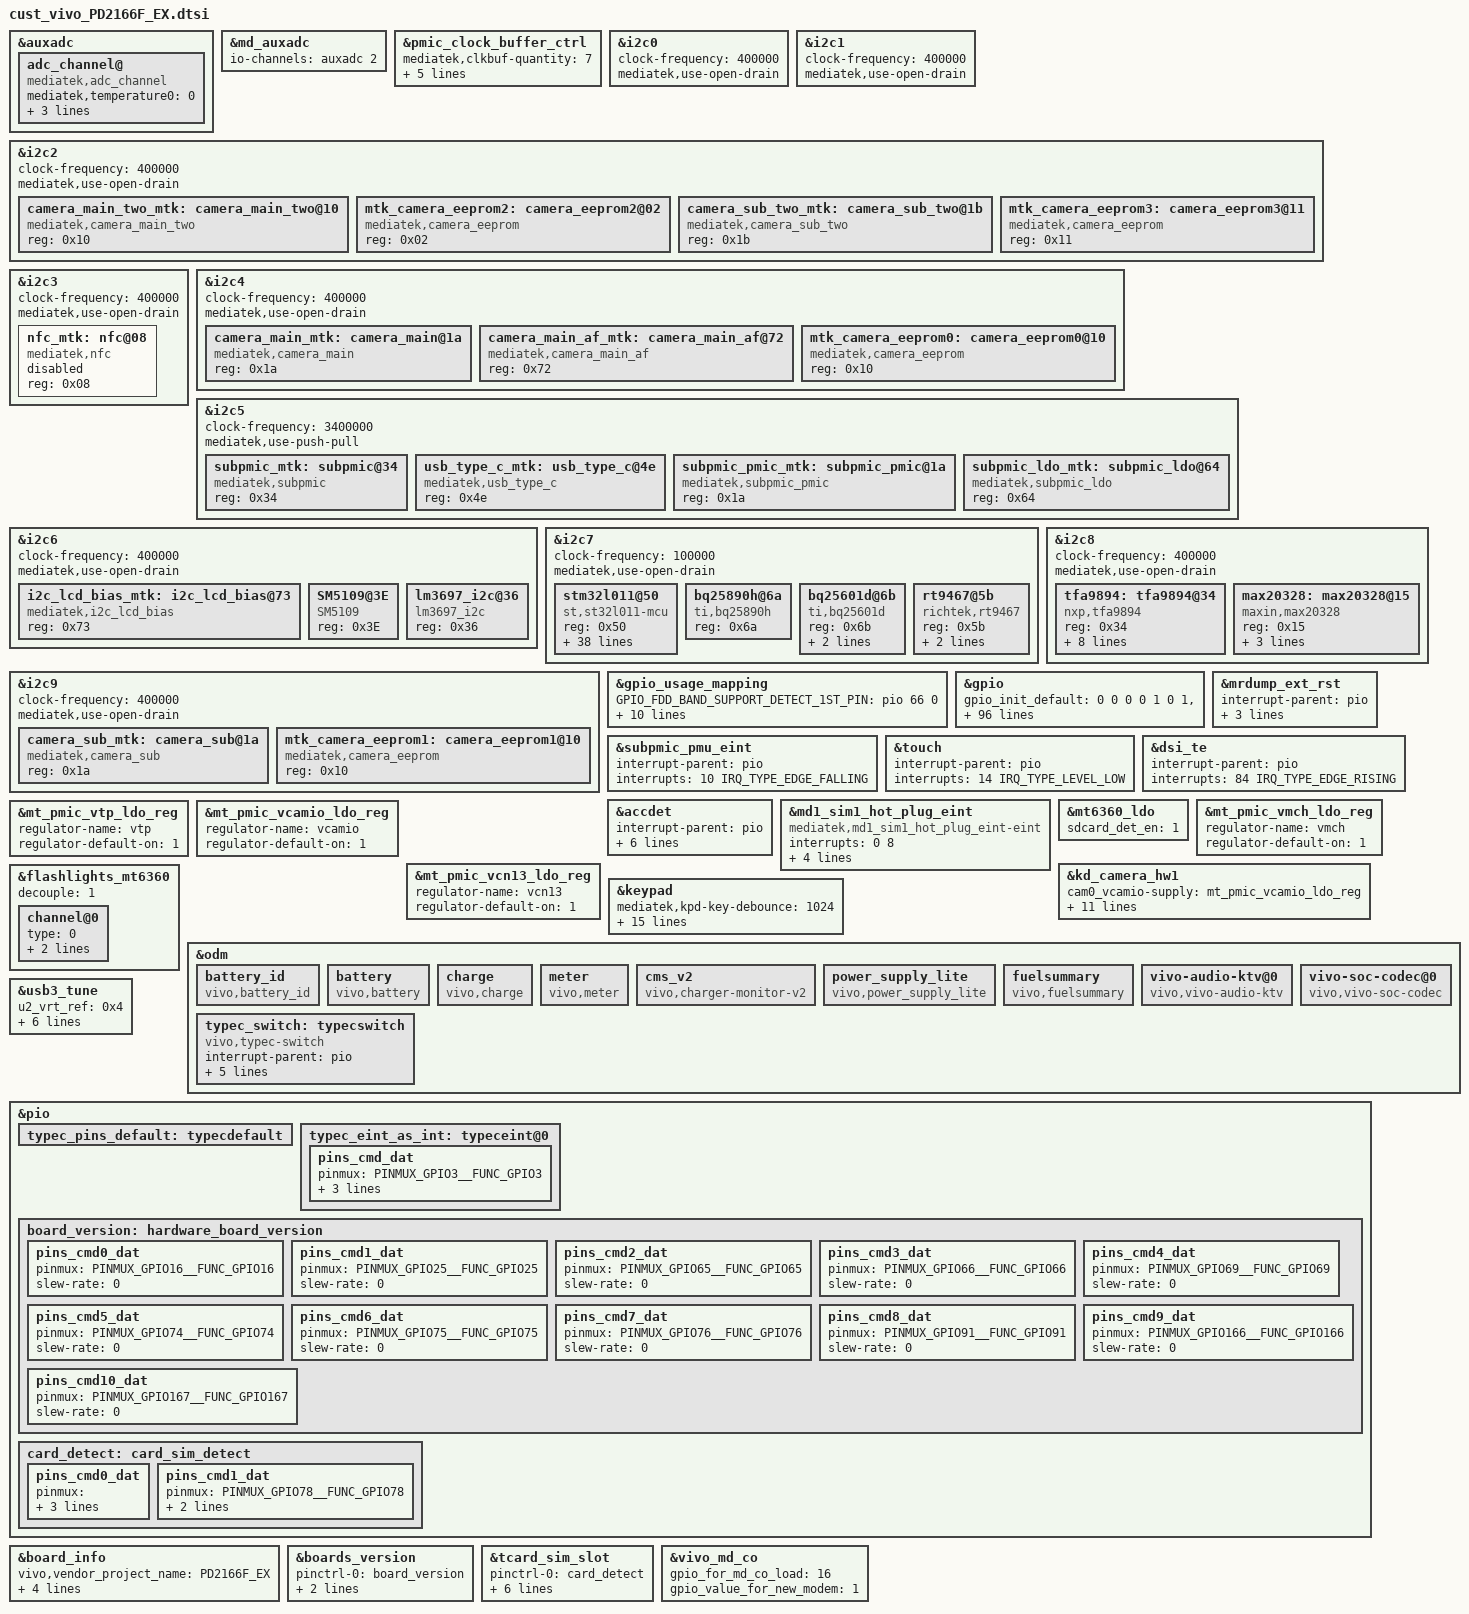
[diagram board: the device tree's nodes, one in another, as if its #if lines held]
/*
 * Generated by MTK SP DrvGen Version: 3.5.160809 for MT6833.
 * 2021-08-25 23:23:21
 * Do Not Modify The File.
 * Copyright Mediatek Inc. (c) 2016.
*/

/*************************
 * ADC DTSI File
*************************/

&auxadc {
	adc_channel@ {
		compatible = "mediatek,adc_channel";
		mediatek,temperature0 = <0>;
		mediatek,temperature1 = <1>;
		mediatek,adc_fdd_rf_params_dynamic_custom_ch = <2>;
		status = "okay";
	};
};
&md_auxadc {
	io-channels = <&auxadc 2>;
};


/*************************
 * CLK_BUF DTSI File
*************************/

&pmic_clock_buffer_ctrl {
	mediatek,clkbuf-quantity = <7>;
	mediatek,clkbuf-config = <2 1 2 2 0 0 1>;
	mediatek,clkbuf-output-impedance = <6 4 4 4 0 0 4>;
	mediatek,clkbuf-controls-for-desense = <0 4 0 4 0 0 0>;
	status = "okay";
};


/*************************
 * I2C DTSI File
*************************/

&i2c0 {
	#address-cells = <1>;
	#size-cells = <0>;
	clock-frequency = <400000>;
	mediatek,use-open-drain;
};

&i2c1 {
	#address-cells = <1>;
	#size-cells = <0>;
	clock-frequency = <400000>;
	mediatek,use-open-drain;
};

&i2c2 {
	#address-cells = <1>;
	#size-cells = <0>;
	clock-frequency = <400000>;
	mediatek,use-open-drain;

	camera_main_two_mtk:camera_main_two@10 {
		compatible = "mediatek,camera_main_two";
		reg = <0x10>;
		status = "okay";
	};
	mtk_camera_eeprom2:camera_eeprom2@02 {
		compatible = "mediatek,camera_eeprom";
		reg = <0x02>;
		status = "okay";
	};
	camera_sub_two_mtk:camera_sub_two@1b {
		compatible = "mediatek,camera_sub_two";
		reg = <0x1b>;
		status = "okay";
	};

	mtk_camera_eeprom3:camera_eeprom3@11 {
		compatible = "mediatek,camera_eeprom";
		reg = <0x11>;
		status = "okay";
	};
};

&i2c3 {
	#address-cells = <1>;
	#size-cells = <0>;
	clock-frequency = <400000>;
	mediatek,use-open-drain;
	nfc_mtk:nfc@08 {
		compatible = "mediatek,nfc";
		reg = <0x08>;
		status = "disabled";
	};

};

&i2c4 {
	#address-cells = <1>;
	#size-cells = <0>;
	clock-frequency = <400000>;
	mediatek,use-open-drain;
	camera_main_mtk:camera_main@1a {
		compatible = "mediatek,camera_main";
		reg = <0x1a>;
		status = "okay";
	};
	camera_main_af_mtk:camera_main_af@72 {
		compatible = "mediatek,camera_main_af";
		reg = <0x72>;
		status = "okay";
	};

	mtk_camera_eeprom0:camera_eeprom0@10 {
		compatible = "mediatek,camera_eeprom";
		reg = <0x10>;
		status = "okay";
	};

};

&i2c5 {
	#address-cells = <1>;
	#size-cells = <0>;
	clock-frequency = <3400000>;
	mediatek,use-push-pull;
	subpmic_mtk:subpmic@34 {
		compatible = "mediatek,subpmic";
		reg = <0x34>;
		status = "okay";
	};

	usb_type_c_mtk:usb_type_c@4e {
		compatible = "mediatek,usb_type_c";
		reg = <0x4e>;
		status = "okay";
	};

	subpmic_pmic_mtk:subpmic_pmic@1a {
		compatible = "mediatek,subpmic_pmic";
		reg = <0x1a>;
		status = "okay";
	};

	subpmic_ldo_mtk:subpmic_ldo@64 {
		compatible = "mediatek,subpmic_ldo";
		reg = <0x64>;
		status = "okay";
	};

};

&i2c6 {
	#address-cells = <1>;
	#size-cells = <0>;
	clock-frequency = <400000>;
	mediatek,use-open-drain;
	i2c_lcd_bias_mtk:i2c_lcd_bias@73 {
		compatible = "mediatek,i2c_lcd_bias";
		reg = <0x73>;
		status = "okay";
	};
	SM5109@3E {
		compatible = "SM5109";
		reg = <0x3E>;
		status = "okay";
	};
	lm3697_i2c@36 {
		compatible = "lm3697_i2c";
		reg = <0x36>;
		status = "okay";
	};
};

&i2c7 {
	#address-cells = <1>;
	#size-cells = <0>;
	clock-frequency = <400000>;
	mediatek,use-open-drain;
};

&i2c8 {
	#address-cells = <1>;
	#size-cells = <0>;
	clock-frequency = <400000>;
	mediatek,use-open-drain;
	

};

&i2c9 {
	#address-cells = <1>;
	#size-cells = <0>;
	clock-frequency = <400000>;
	mediatek,use-open-drain;
	
	camera_sub_mtk:camera_sub@1a {
		compatible = "mediatek,camera_sub";
		reg = <0x1a>;
		status = "okay";
	};

	mtk_camera_eeprom1:camera_eeprom1@10 {
		compatible = "mediatek,camera_eeprom";
		reg = <0x10>;
		status = "okay";
	};

};



/*************************
 * GPIO DTSI File
*************************/

&gpio_usage_mapping {
	GPIO_FDD_BAND_SUPPORT_DETECT_1ST_PIN = <&pio 66 0>;
	GPIO_FDD_BAND_SUPPORT_DETECT_2ND_PIN = <&pio 65 0>;
	GPIO_FDD_BAND_SUPPORT_DETECT_3RD_PIN = <&pio 25 0>;
	GPIO_SIM1_HOT_PLUG = <&pio 77 0>;
	GPIO_SIM2_SCLK = <&pio 119 0>;
	GPIO_SIM2_SRST = <&pio 120 0>;
	GPIO_SIM2_SIO = <&pio 121 0>;
	GPIO_SIM1_SIO = <&pio 122 0>;
	GPIO_SIM1_SRST = <&pio 123 0>;
	GPIO_SIM1_SCLK = <&pio 124 0>;
	GPIO_RF_PWREN_RST_PIN = <&pio 170 0>;
};

&gpio{
	gpio_init_default = <0 0 0 0 1 0 1>,
		<1 0 0 0 1 1 1>,
		<2 0 0 0 1 1 1>,
		<3 0 0 0 1 0 1>,
		<4 0 0 0 1 1 1>,
		<5 0 0 0 1 0 1>,
		<6 0 1 0 1 0 1>,
		<7 0 1 0 1 0 1>,
		<8 7 0 0 1 0 1>,
		<9 0 0 0 1 1 1>,
		<10 0 0 0 1 1 1>,
		<11 0 0 0 1 1 1>,
		<12 2 0 0 1 0 1>,
		<13 2 0 0 1 0 1>,
		<14 0 0 0 1 1 1>,
		<15 0 1 0 1 0 1>,
		<16 0 0 0 1 1 0>,
		<17 7 0 0 1 0 1>,
		<18 7 0 0 1 0 1>,
		<19 7 0 0 0 0 1>,
		<20 7 0 0 1 0 1>,
		<21 0 0 0 0 0 1>,
		<22 7 0 0 1 0 1>,
		<23 7 0 0 1 0 1>,
		<24 7 0 0 1 0 1>,
		<25 0 0 0 1 1 0>,
		<26 7 0 0 1 0 1>,
		<27 1 0 0 0 0 1>,
		<28 1 0 0 0 0 1>,
		<29 1 0 0 0 0 1>,
		<30 1 0 0 1 0 1>,
		<31 2 0 0 0 0 1>,
		<32 2 0 0 0 0 1>,
		<33 2 0 0 0 0 1>,
		<34 2 0 0 1 0 1>,
		<35 0 1 0 1 0 1>,
		<36 0 1 0 1 0 1>,
		<37 0 1 0 1 0 1>,
		<38 0 1 0 1 0 1>,
		<39 0 0 0 1 1 1>,
		<40 1 0 0 0 0 1>,
		<41 1 0 0 0 0 1>,
		<42 1 0 0 1 0 1>,
		<43 1 0 0 0 0 1>,
		<44 0 1 0 1 1 1>,
		<45 0 1 1 0 0 0>,
		<46 0 0 0 1 0 1>,
		<47 0 0 0 0 0 1>,
		<48 0 0 0 0 0 1>,
		<49 1 1 0 0 0 0>, //CAM0 clk0
		<50 1 1 0 0 0 0>, //CAM3 clk1
		<51 1 1 0 0 0 0>, //CAM2 clk2
		<52 1 1 0 0 0 0>, //CAM1 clk3
		<53 0 1 0 1 0 1>, //cam0 AVDD
		<54 0 1 0 0 0 0>, //CAM0 RST 
		<55 0 1 0 0 0 0>, //cam123 AVDD
		<56 0 1 0 0 0 0>, //CAM3 RST
		<57 0 0 0 1 0 1>,
		<58 0 1 0 0 0 0>, //CAM2 RST
		<59 0 1 0 0 0 0>, //cam0 DVDD
		<60 0 1 0 0 0 0>, //CAM1 RST
		<61 1 0 0 1 1 1>,
		<62 1 0 0 0 0 1>,
		<63 1 0 0 1 1 1>,
		<64 1 0 0 0 0 1>,
		<65 0 0 0 1 1 0>,
		<66 0 0 0 1 1 0>,
		<67 0 1 0 1 1 0>,
		<69 0 0 0 1 1 0>,
		<74 0 0 0 1 1 0>,
		<75 0 0 0 1 1 0>,
		<76 0 0 0 1 1 0>,
		<77 1 0 0 0 0 1>,
		<78 0 0 0 0 0 1>,
		<79 1 0 0 1 1 1>,
		<80 0 1 0 1 0 1>,
		<81 3 0 0 1 0 1>,
		<82 0 1 0 1 0 1>,
		<83 1 0 0 0 0 1>,
		<84 1 0 0 1 0 1>,
		<85 1 0 0 0 0 1>,
		<86 0 0 0 0 0 1>,
		<87 2 0 0 1 0 1>,
		<88 1 0 0 1 0 1>,
		<89 0 0 0 1 0 1>,
		<90 0 0 0 0 0 1>,
		<91 0 0 0 1 0 1>,
		<92 0 1 0 1 0 1>,
		<93 0 1 0 1 0 1>,
		<94 0 1 0 1 0 1>,
		<95 1 0 0 1 0 1>,
		<96 1 0 0 1 0 1>,
		<97 2 0 0 1 1 1>,
		<98 2 0 0 1 1 1>,
		<99 2 0 0 1 1 1>,
		<100 2 0 0 1 1 1>,
		<101 1 0 0 0 0 1>, //scl2 iic2
		<102 1 0 0 0 0 1>, //sda2 iic2
		<103 1 0 0 1 1 1>,
		<104 1 0 0 1 1 1>,
		<105 1 0 0 0 0 1>, //scl4 iic4
		<106 1 0 0 0 0 1>, //sda4 iic4
		<107 1 0 0 1 1 1>,
		<108 1 0 0 1 1 1>,
		<109 1 0 0 1 1 1>,
		<110 1 0 0 1 1 1>,
		<111 1 0 0 1 1 1>,
		<112 1 0 0 1 1 1>,
		<113 1 0 0 1 1 1>,
		<114 1 0 0 1 1 1>,
		<115 1 0 0 1 0 1>,
		<116 1 0 0 1 0 1>,
		<117 0 0 0 1 0 1>,
		<118 0 0 0 1 0 1>,
		<119 1 0 0 0 0 1>,
		<120 1 0 0 0 0 1>,
		<121 1 0 0 1 1 1>,
		<122 1 0 0 1 1 1>,
		<123 1 0 0 0 0 1>,
		<124 1 0 0 0 0 1>,
		<125 1 0 0 0 0 1>,
		<126 1 0 0 1 1 1>,
		<127 1 0 0 1 1 1>,
		<128 1 0 0 1 1 1>,
		<129 1 0 0 1 1 1>,
		<130 1 0 0 1 1 1>,
		<131 0 1 0 1 0 1>,
		<132 0 1 0 1 0 1>,
		<133 0 1 0 1 0 1>,
		<134 0 1 0 1 0 1>,
		<135 0 1 0 1 0 1>,
		<136 0 1 1 1 0 1>,
		<137 0 1 0 1 0 1>,
		<138 0 1 0 1 0 1>,
		<139 0 1 0 1 0 1>,
		<140 0 1 0 1 0 1>,
		<141 1 0 0 0 0 1>, //scl9 iic9
		<142 1 0 0 0 0 1>, //sda9 iic9
		<143 1 0 0 0 0 1>,
		<144 1 0 0 0 0 1>,
		<145 1 0 0 0 0 1>,
		<146 1 0 0 0 0 1>,
		<147 1 0 0 0 0 1>,
		<148 1 0 0 0 0 1>,
		<149 1 0 0 1 0 1>,
		<150 1 0 0 1 0 1>,
		<151 1 0 0 1 0 1>,
		<152 1 0 0 1 0 1>,
		<153 1 0 0 0 0 1>,
		<154 1 0 0 0 0 1>,
		<155 1 0 0 0 0 1>,
		<156 1 0 0 0 0 1>,
		<157 1 0 0 0 0 1>,
		<158 1 0 0 0 0 1>,
		<159 1 0 0 1 0 1>,
		<160 1 0 0 1 0 1>,
		<161 1 0 0 1 0 1>,
		<162 1 0 0 0 0 0>,
		<163 1 0 0 1 0 0>,
		<164 1 0 0 1 0 1>,
		<165 1 0 0 1 0 1>,
		<166 0 0 0 1 1 0>,
		<167 0 0 0 1 1 0>,
		<168 1 0 0 0 0 1>,
		<169 1 0 0 0 0 1>,
		<170 0 1 1 1 0 1>,
		<171 1 0 0 0 0 1>,
		<172 1 0 0 0 0 1>,
		<173 1 0 0 0 0 1>,
		<174 1 0 0 0 0 1>,
		<175 1 0 0 0 0 1>,
		<176 1 0 0 0 0 1>,
		<177 1 0 0 0 0 1>,
		<178 1 0 0 0 0 1>,
		<179 1 0 0 0 0 1>,
		<180 1 0 0 0 0 1>,
		<181 1 0 0 0 0 1>,
		<182 1 0 0 0 0 1>,
		<183 1 0 0 0 0 1>,
		<184 1 0 0 0 0 1>,
		<185 1 0 0 0 0 1>,
		<186 1 0 0 0 0 1>,
		<187 0 1 0 1 0 1>,
		<188 1 0 0 0 0 0>,
		<189 1 0 0 1 0 0>,
		<190 1 0 0 0 0 0>,
		<191 1 0 0 1 0 0>,
		<192 0 0 0 1 0 1>,
		<193 0 0 0 1 0 1>,
		<194 0 0 0 1 0 1>,
		<195 0 0 0 1 0 1>,
		<196 0 0 0 1 0 1>,
		<197 0 0 0 1 0 1>,
		<198 0 0 0 1 0 1>,
		<199 0 0 0 1 0 1>,
		<200 0 0 0 1 0 1>;
};


/*************************
 * EINT DTSI File
*************************/

#include <dt-bindings/interrupt-controller/irq.h>
#include <dt-bindings/interrupt-controller/arm-gic.h>

&mrdump_ext_rst {
	interrupt-parent = <&pio>;
	interrupts = <1 IRQ_TYPE_LEVEL_LOW>;
	deb-gpios = <&pio 1 0>;
	debounce = <512000>;
	status = "okay";
};

&subpmic_pmu_eint {
	interrupt-parent = <&pio>;
	interrupts = <10 IRQ_TYPE_EDGE_FALLING>;
	status = "okay";
};

&touch {
	interrupt-parent = <&pio>;
	interrupts = <14 IRQ_TYPE_LEVEL_LOW>;
	status = "okay";
};

&dsi_te {
	interrupt-parent = <&pio>;
	interrupts = <84 IRQ_TYPE_EDGE_RISING>;
	status = "okay";
};

&accdet {
	interrupt-parent = <&pio>;
	interrupts = <2 IRQ_TYPE_LEVEL_LOW>,
			<3 IRQ_TYPE_LEVEL_LOW>;
	deb-gpios = <&pio 2 0>;
	deb-rgpios = <&pio 3 0>;
	debounce = <256000>;
	debounce1 = <256000>;
	status = "okay";
};


/*************************
 * MD1_EINT DTSI File
*************************/

&md1_sim1_hot_plug_eint {
	compatible = "mediatek,md1_sim1_hot_plug_eint-eint";
	interrupts = <0 8>;
	debounce = <0 100000>;
	dedicated = <0 0>;
	src_pin = <0 1>;
	sockettype = <0 0>;
	status = "okay";
};


/*************************
 * PMIC DTSI File
*************************/
&mt6360_ldo {
	sdcard_det_en = <1>;
};

&mt_pmic_vmch_ldo_reg {
	regulator-name = "vmch";
	regulator-default-on = <1>; /* 0:skip, 1: off, 2:on */
	status = "okay";
};

&mt_pmic_vtp_ldo_reg {
	regulator-name = "vmch";
	regulator-default-on = <1>; /* 0:skip, 1: off, 2:on */
	status = "okay";
};
&mt_pmic_vcamio_ldo_reg {
	regulator-name = "vcamio";
	regulator-default-on = <1>; /* 0:skip, 1: off, 2:on */
	status = "okay";
};
&mt_pmic_vtp_ldo_reg {
	regulator-name = "vtp";
	regulator-default-on = <1>; /* 0:skip, 1: off, 2:on */
	status = "okay";
};

&mt_pmic_vcn13_ldo_reg{
	regulator-name = "vcn13";
	regulator-default-on = <1>; /* 0:skip, 1: off, 2:on */
	status = "okay";
};
&kd_camera_hw1 {
	cam0_vcamio-supply = <&mt_pmic_vcamio_ldo_reg>;/*6365 vcamio*/
	cam1_vcamio-supply = <&mt_pmic_vcamio_ldo_reg>;
	cam2_vcamio-supply = <&mt_pmic_vcamio_ldo_reg>;
	cam3_vcamio-supply = <&mt_pmic_vcamio_ldo_reg>;
	cam1_vcamd-supply = <&mt_pmic_vcn13_ldo_reg>;/*6365 DVDD*/
	cam0_vcamaf_def-supply = <&mt_pmic_vtp_ldo_reg>;/*6360 AF*/
	cam0_enable_sensor = "s5kjn1sq03pd2166_mipi_raw ov13b10pd2166_mipi_raw";
	cam1_enable_sensor = "s5k4h7pd2166_mipi_raw hi1634qpd2166_mipi_raw";
	cam2_enable_sensor = "gc02m1pd2166_mipi_raw";
	cam3_enable_sensor = "gc02m1bpd2166_mipi_mono";
	status = "okay";
};

&camera_main_af_mtk{
         //vcamaf-supply = <&mt_pmic_vtp_ldo_reg>;
         status = "okay";
};

&flashlights_mt6360 {
	decouple = <1>;
	channel@0 {
			type = <0>;
			ct = <0>;
			part = <0>;
	};
};

/*************************
 * POWER DTSI File
*************************/



/*************************
 * KPD DTSI File
*************************/

&keypad {
	mediatek,kpd-key-debounce = <1024>;
	mediatek,kpd-sw-pwrkey = <116>;
	mediatek,kpd-hw-pwrkey = <8>;
	mediatek,kpd-sw-rstkey  = <114>;
	mediatek,kpd-hw-rstkey = <17>;
	mediatek,kpd-use-extend-type = <0>;
	/*HW Keycode [0~71] -> Linux Keycode*/
	mediatek,kpd-hw-map-num = <72>;
	mediatek,kpd-hw-init-map = <115 0 0 0 0 0 0 0 0 0 0 0 0 0 0 0 0 0 0 0 0 0 0 0 0 0 0 0 0 0 0 0 0 0 0 0 0 0 0 0 0 0 0 0 0 0 0 0 0 0 0 0 0 0 0 0 0 0 0 0 0 0 0 0 0 0 0 0 0 0 0 0 >;
	mediatek,kpd-pwrkey-eint-gpio = <0>;
	mediatek,kpd-pwkey-gpio-din  = <0>;
	mediatek,kpd-hw-dl-key0 = <17>;
	mediatek,kpd-hw-dl-key1 = <0>;
	mediatek,kpd-hw-dl-key2 = <8>;
	mediatek,kpd-hw-recovery-key = <17>;
	mediatek,kpd-hw-factory-key = <0>;
	status = "okay";
};

/* Chris Lee add for battery&charge start */
#ifdef CONFIG_VIVO_CHARGING_NEW_ARCH
#ifdef CONFIG_VIVO_CHARGING_DTS_MOVE_HEAD_FILE
&odm {
	battery_id {
		compatible = "vivo,battery_id";
		status = "okay";
	};

	battery: battery {
		compatible = "vivo,battery";
		status = "okay";
	};

	charge: charge {
		compatible = "vivo,charge";
		status = "okay";
	};

	meter: meter {
		compatible = "vivo,meter";
		status = "okay";
	};

	cms_v2: cms_v2 {
		compatible = "vivo,charger-monitor-v2";
		status = "okay";
	};

	power_supply_lite: power_supply_lite {
		compatible = "vivo,power_supply_lite";
		status = "okay";
	};

	fuelsummary: fuelsummary {
		compatible = "vivo,fuelsummary";
		status = "okay";
	};
};

#else

&battery_id {
	status = "okay";
	compatible = "vivo,battery_id";

	vivo,bat-adc-ctrl-gpio = <&pio 131 0>;

	io-channels = <&auxadc 3>;
	io-channel-names = "battery_id_adc";

	vivo,bat-name = "UNKNOWN","B-O8 ATL-FMT 4910","B-O8 LW-XWD 4910", "B-O8 ATL-XDN 4910";
};

&battery {
	status = "okay";
	compatible = "vivo,battery";

	io-channels = <&auxadc 0>,
		<&auxadc 4>;
	io-channel-names = "primary_board_therm",
		"parallel_board_therm";

	vivo,low-volt-threshold = <3400>;
	vivo,soft-rise-percent = <90>;
	vivo,soft-rise-cumulative = <10>;
	vivo,soft-rise-keep-cumulative = <14>;
	vivo,percnet-sync-delta = <4>;
	vivo,percnet-sync-cumulative = <9>;
	vivo,full-sync-cumulative = <3>;
	vivo,soft-term-percent = <99>;
	vivo,soft-term-cumulative = <48>;
};

&charge {
	status = "okay";
	compatible = "vivo,charge";

	vivo,chg-wdt-s = <40>;
	vivo,re-chg-voltage-mv = <100>;
	vivo,prechg-voltage-mv = <3000>;
	vivo,iprechg-current-ma = <300>;
	vivo,iterm-current-ma = <256>;
	vivo,vreg-voltage-mv = <4430>;
	vivo,vindpm-voltage-mv = <4600>;
	vivo,sys-voltage-min-mv= <3300>;
	vivo,boostv-voltage-mv = <5150>;
	vivo,boostv-ilimit-ma = <1800>;
	vivo,ovp-voltage-mv = <15000>;

	vivo,battery-id-vreg-mv = <4430 4430 4430 4430 4430 4430>;
	/*
	 * 0  auto detect charging
	 * 1  vivo-normal chargine
	 * 2  vivo-single engine charging
	 * 3  vivo-dual engine charging
	 * 4  vivo-flash charging
	 */
	vivo,charge-scheme = <0>;
	vivo,direct-charger-enable;

	/*
	 * SUPPORTED_ADAPTER_DEFAULT = 0,
	 * SUPPORTED_ADAPTER_VIVO_LV_DCHG_5V_4500MA = 1,
	 * SUPPORTED_ADAPTER_VIVO_HV_DCHG_10V_2250MA = 2,
	 * SUPPORTED_ADAPTER_QC20__9V_2000MA = 3,
	 * SUPPORTED_ADAPTER_VIVO_HV_DCHG_10V_4000MA = 4,
	 * SUPPORTED_ADAPTER_MAX,
	 */
	vivo,supported-adapter = <3>;

	//parameter for 9V2A
	vivo,primary-ichg-max-ma = <2048>;
	vivo,parallel-ichg-max-ma = <1720>;

	vivo,flashchg-spec-ma = <2000 3300 8000>;
	vivo,fastchg-spec-ma = <2000 2100 3800>;
	vivo,normalchg-spec-ma = <2000 1500 2300>;

	/* 0---PMIC; 1---CHGIC */
	vivo,vbus-detect-source = <1>;

	//vivo,usboe-gpio = <&pio 184 0>;

	/*ffc*/
	//vivo,ffc-enable;
	vivo,ffc-iterm-ma = <(-750)>;
	vivo,ffc-vreg-mv = <4520>;
	vivo,ffc-temperature-range = <150 450>;
	vivo,ffc-full-vbat-table-size = <3>;
	vivo,ffc-full-vbat-table = <4534 4520 4520>;
	vivo,ffc-full-ibat-table-size = <3>;
	vivo,ffc-full-ibat-table = <150 199 (-699)>,
		<200 349 (-958)>,
		<350 449 (-1137)>;
};

&meter {
	status = "okay";
	compatible = "vivo,meter";

	vivo,load-capacity-delta-max = <60>;
	vivo,poweron-delta-capacity = <20>;
	vivo,poweron-low-capacity = <3>;
	vivo,volt-car-delta = <8>;
	vivo,car-volt-delta = <6>;
	vivo,meter-res-compesate = <10>;
	vivo,ocv-board-compesate = <0>;

	/* 0---AGING_UNSUPPORTED; 1---DRIVER_SUPPORTED; 2---USPACE_SUPPORTED */
	vivo,battery-aging-support = <2>;

	vivo,capacity-mAh = <4910>;
	/*COLD_CHG COLD_DISCHG NORMAL_CHG NORMAL_DISCHG*/
	vivo,car-tune-value = <1000 1000 1000 1000>,
		<1000 1000 1000 1000>,
		<1000 1000 1000 1000>,
		<1030 1010 1050 1010>,
		<1000 1000 1000 1000>,
		<1000 1000 1000 1000>;

	vivo,bats-qmax = <3270 3460 3440 3790 3870>,
		<4250 4380 4741 4970 4950>,
		<3450 4150 4660 4780 4799>,
		<4300 4450 4700 4970 4975>,
		<3276 3346 3458 3524 3514>,
		<3600 3677 3800 3873 3862>;

	/* car-tune adjust remap */
	vivo,car-tune-adjust-enable;
	vivo,car-tune-adjust-size = <3>;
	vivo,car-tune-adjust-table = <0 10 (340) 7>,
		<11 20 (-30) 10>,
		<21 100 (-30) 11>;

	#include "bat_setting/PD2166_battery_table.dtsi"
};

&cms_v2 {
	compatible = "vivo,charger-monitor-v2";
	status = "okay";

	default_board: single_charger_board {
		       /*default board: keep in xxxxxx*/
		       support-board-version = "xxxxxx";

		       vivo,bat-det-method = <0>;//r:0, rc:1, eprom:2, ex-fg:3
		       vivo,bat-id-gpio = <&pio 131 0>;
				#include "bat_setting/PD2166_battery_chg_params.dtsi"

		       /*
			  CHG0__CHARGING_TECHNOLOGY_NONE = 0,
			  CHG1__NORMAL_CHARGING,			//5V/2A normal charging
			  CHG2__QC2_CHARGING,				//9V/2A	QC2.0 charging
			  CHG3__LOW_VOLTAGE_DIRECT_CHARGING,		//5V/4.5A direct charging
			  CHG4__SINGLE_IC_DIV2_CHARGING,		//single IC Div/2 charging
			  CHG5__DUAL_IC_DIV2_CHARGING,			//Dual IC Div/2 charging
			  CHG6__DUAL_IC_DUAL_BATTERY_DIV2_CHARGING,	//Dual IC Div/2 charging
			  CHGX__CHARGING_TECHNOLOGY_MAX,
			*/
		       vivo,charging-technology = <2>;

		       //vivo,no-bat-warning;
		       //vivo,no-chg-timeout;
		       vivo,chg-timeout-mins = <900>;

		       //high temperature charger current control enable
		       vivo,htccc-enable;
		       vivo,htccc-data = <46 53 4100000 100000>;

		       //vivo,fbon-scale-enable;/*disable default*/
		       vivo,fbon-scale-data = <2 100 100>;

		       //vivo,switch-scale-enable;/*disable from rom4.0*/
		       vivo,switch-scale-data = <75 53>;

		       vivo,calling-scale-enable;
		       vivo,calling-scale-data = <100 21>;/*ibat:3900 * 0.54 = 2106,more than 1500,not exit dchg*/
		       vivo,calling-dchg-disable;

		       vivo,weixin-calling-scale-enable;
		       vivo,weixin-calling-scale-data = <100 112>;/*5000mA*/

		       //vivo,fixed-scale-enable;
		       vivo,fixed-scale-data = <120 3800 0>;/*dchg fixed time adjust the max ibat,disable default*/

		       /*data processing : batt-temp*/
		       vivo,dp-batt-temp-enable;
		       vivo,dp-batt-temp-data = <100>;

		       /* charging current for devices in exhibition mode */
		       vivo,exhibition-mode-current-primary = <2048>;
		       vivo,exhibition-mode-current-parallel = <0>;

		       /*default tc parameter*/
		       //single charger ibat scale base on temperature battery cell info:1C/1.2C 3960mah
		       /* tmin, tmax, data, volt1, data_ex1, volt2, data_ex2. */
		        vivo,normal-tc-row-col = <6 9>;
		       vivo,normal-tc-data = <530 8888 0 0 0 0 0 0 0>,
			       <450 529 65 0 0 0 0 0 0>,
			       <150 449 78 0 0 0 0 0 0>,
			       <100 149 78 4200000 54 0 0 0 0>,
			       <20 99 54 0 0 0 0 0 0>,
			       <(-8888) 19 0 0 0 0 0 0 0>;

		       /*flash tc parameter*/
		       vivo,flash-normal-tc-row-col = <9 9>;
		       vivo,flash-normal-tc-data = <550 8888 0 0 0 0 0 0 0>,
			       <450 549 50 0 0 0 0 0 0>,
			       <350 449 202 4200000 152 4300000 120 4460000 90>,
			       <200 349 202 4200000 152 4300000 120 4460000 90>,
			       <150 199 152 4200000 121 4460000 80 0 0>,
			       <100 149 100 0 0 0 0 0 0>,
			       <50 99 70 4200000 50 0 0 0 0>,
			       <0 49 50 0 0 0 0 0 0>,
			       <(-8888) (-1) 0 0 0 0 0 0 0>;

		       /*adjust fastchg base on board temperature and fb off*/
		       vivo,intell-charge-enable;
		       vivo,parallel-temp-enable = <1 1>;//<x y> x:fb-on y:fb-off

		       /* Flash charge fb-on intell param */
		       vivo,primary-fbon-tc-row-col = <7 3>;
		       vivo,primary-fbon-tc-data = <421 8888 1600>,
			       <411 420 2300>,
			       <401 410 3300>,
			       <391 400 3800>,
			       <381 390 4300>,
			       <361 380 6000>,
			       <(-8888) 360 8000>;

		       vivo,parallel-fbon-tc-row-col = <1 3>;
		       vivo,parallel-fbon-tc-data = <(-8888) 8888 0>;

		       /* Flash charge fb-off intell param */
		       vivo,primary-fboff-tc-row-col = <6 3>;
		       vivo,primary-fboff-tc-data = <421 8888 1600>,
			       <409 420 3100>,
			       <390 408 4000>,
			       <371 389 4300>,
			       <351 370 5200>,
			       <(-8888) 350 8000>;
		       vivo,parallel-fboff-tc-row-col = <1 3>;
		       vivo,parallel-fboff-tc-data = <(-8888) 8888 0>;

		       /* 9v Fast charge fb-on intell param */
		       vivo,9v-primary-fbon-tc-row-col = <7 3>;
		       vivo,9v-primary-fbon-tc-data = <481 8888 500>,
			       <471 480 700>,
			       <451 470 1000>,
			       <421 450 1500>,
			       <391 420 1600>,
			       <371 390 1800>,
			       <(-8888) 370 2000>;
		       vivo,9v-parallel-fbon-tc-row-col = <8 3>;
		       vivo,9v-parallel-fbon-tc-data = <461 8888 0>,
					<451 460 300>,
					<431 450 500>,
			       <411 430 600>,
			       <401 410 800>,
			       <381 400 1100>,
			       <361 380 1300>,
			       <(-8888) 360 1500>;
		       // second parallel parameter, for rt9467
		       vivo,9v-2nd-parallel-fbon-tc-row-col = <6 3>;
		       vivo,9v-2nd-parallel-fbon-tc-data = <431 8888 300>,
			       <411 430 500>,
			       <391 410 800>,
			       <371 390 1000>,
			       <351 370 1300>,
			       <(-8888) 350 1500>;


		       /* 9v Fast charge fb-off intell param */
		       vivo,9v-primary-fboff-tc-row-col = <6 3>;
		       vivo,9v-primary-fboff-tc-data = <431 8888 500>,
			       <416 430 1100>,
			       <406 415 1300>,
			       <386 405 1600>,
			       <371 385 1900>,
			       <(-8888) 370 2000>;
		       vivo,9v-parallel-fboff-tc-row-col = <6 3>;
		       vivo,9v-parallel-fboff-tc-data = <431 8888 500>,
			       <411 430 800>,
			       <396 410 1100>,
			       <386 395 1300>,
			       <371 385 1600>,
			       <(-8888) 370 1700>;
		       // second parallel parameter, for rt9467
		       vivo,9v-2nd-parallel-fboff-tc-row-col = <6 3>;
		       vivo,9v-2nd-parallel-fboff-tc-data = <431 8888 500>,
			       <411 430 700>,
			       <386 410 1150>,
			       <376 385 1300>,
			       <371 375 1600>,
			       <(-8888) 370 1700>;


		       /* 5v Normal charge fb-on intell param */
		       vivo,5v-primary-fbon-tc-row-col = <5 3>;
		       vivo,5v-primary-fbon-tc-data = <441 8888 500>,
					<431 440 800>,
			       <421 430 1000>,
			       <411 420 1500>,
			       <(-8888) 410 2000>;
		       vivo,5v-parallel-fbon-tc-row-col = <1 3>;
		       vivo,5v-parallel-fbon-tc-data = <(-8888) 8888 0>;

		       /* 5v Normal charge fb-off intell param */
		       vivo,5v-primary-fboff-tc-row-col = <5 3>;
		       vivo,5v-primary-fboff-tc-data = <441 8888 500>,
					<431 440 800>,
			       <421 430 1000>,
			       <411 420 1500>,
			       <(-8888) 410 2000>;
		       vivo,5v-parallel-fboff-tc-row-col = <1 3>;
		       vivo,5v-parallel-fboff-tc-data = <(-8888) 8888 0>;

		       // Direct charging param
		       vivo,direct-charger-enable;//porting_check
		       vivo,ex-bms-psy-name = "bq_bms";

		       // bat_baord, usb_conn, pcb_conn(master_bat_conn), bat_conn
		       vivo,dchg-ntc-protect-enable;
		       vivo,dchg-ntc-protect-data = <750 800 850 850>;

		       vivo,adapter-cooldown-data = <900 850 3400>;
		       /*adapter power derate*/
		       vivo,adapter-power-derate-enable;

		       /* usb connecter protect param
			* USB_PROTECT_NONE = 0,
			* USB_CONN_TEMP_HEAT_PROTECT = BIT(0),
			* USB_ID_PROTECT = BIT(1),
			*/
		       vivo,usb-connecter-protect-enable = <1>;
		       vivo,usb-id-protect-data= <1100 1547 500>;/* 500K, 2M, fcc */
		       vivo,usb-conn-heat-protect-data-row-col = <2 4>;
		       vivo,usb-conn-heat-protect-data= <260 8888 670 620>,
			       <(-8888) 259 570 520>;

		       /*
			* max vbus of adapter:11v, max ibus of adapter:5A
			* min voltage of battery for half chg:3500mV,max voltage of battery for half charge:4100mV,
			* 5V2A charge min current threshold: 1000mA,5V2A charge max current threshold:2100mA,
			* flash charge min current threshold:5000mA,flash charge max current threshold:11000mA
			*/

		       /*default parameter*/
		       vivo,charge-param-judge-threshold = <9 2 3500 4300 1000 2100 2100 4600>;
		       /* factory mode charging test param */
		       vivo,charge-test-param-row-col = <12 3>;
		       vivo,charge-test-param-data = <0 0 5500>, /* cable resistance, min value, max value */
			       <0 0 5500>, /* master ibus, min ibus, max ibus */
			       <0 0 5500>, /* slave ibus, min ibus, max ibus */
			       <1 20 40>, /* batt therm ntc, min value, max value */
			       <1 20 45>, /* board therm ntc, min value, max value */
			       <0 20 50>, /* sub charger ntc, min value, max value */
			       <0 20 45>, /* usb con ntc, min value, max value */
			       <0 20 45>, /* usb con 1 ntc, double usb NTC, min value, max value */
			       <0 20 45>, /* bat btb master ntc, min value, max value */
			       <0 20 50>, /* bat btb sub ntc, min value, max value */
			       <0 20 50>, /* bat board ntc, min value, max value */
			       <0 20 50>; /* wireless charge coil ntc, min value, max value */

		       /*flash parameter*/
		       vivo,flash-charge-param-judge-threshold = <11 3 3500 4100 1000 2200 4000 8200>;
		       /* factory mode charging test param */
		       vivo,flash-charge-test-param-row-col = <12 3>;
		       vivo,flash-charge-test-param-data = <1 0 5500>, /* cable resistance, min value, max value */
			       <1 0 5500>, /* master ibus, min ibus, max ibus */
			       <0 0 5500>, /* slave ibus, min ibus, max ibus */
			       <1 20 40>, /* batt therm ntc, min value, max value */
			       <1 20 45>, /* board therm ntc, min value, max value */
			       <0 20 50>, /* sub charger ntc, min value, max value */
			       <1 20 45>, /* usb con ntc, min value, max value */
			       <0 20 45>, /* usb con 1 ntc, double usb NTC, min value, max value */
			       <1 20 45>, /* bat btb master ntc, min value, max value */
			       <0 20 50>, /* bat btb sub ntc, min value, max value */
			       <0 20 50>, /* bat board ntc, min value, max value */
			       <0 20 50>; /* wireless charge coil ntc, min value, max value */
	       };
};

&power_supply_lite {
	status = "okay";
	compatible = "vivo,power_supply_lite";
};

&fuelsummary {
	status = "okay";
	compatible = "vivo,fuelsummary";

	/************************************************************
	 *
	 *  0   vivo-fastchg
	 *  1   qcom-dualchg
	 *  2   mtk-dualchg
	 *  3   qcom-normchg
	 *  4   mtk-normchg
	 *
	 ***********************************************************/
	chg-scheme = <2>;
	fex-version = <3>;
	fbon-ibat = <(-900)>;
	fboff-ibat = <(-1000)>;

	/* 0---AGING_UNSUPPORTED; 1---DRIVER_SUPPORTED; 2---USPACE_SUPPORTED */
	vivo,battery-aging-support = <2>;
};

#endif

&i2c7 {
	#address-cells = <1>;
	#size-cells = <0>;
	status = "okay";
	clock-frequency = <100000>;

	stm32l011@50 {
		compatible = "st,st32l011-mcu";
		reg = <0x50>;

		//vpower-ldo-supply = <&mt_pmic_vcn33_2_wifi_ldo_reg>;
		vivo,power-gpio = <&pio 74 0>;//ZC_LDO_EN
		vivo,int-gpio = <&pio 8 0>;//MCU_INT_AP
		//vivo,usbsel-gpio = <&pio 8 0>;//USB_SW_EN
		vivo,shift-en-gpio = <&pio 72 0>;//SHIFT_EN
		vivo,chgic-version-gpio = <&pio 16 0>;//°æ±¾Ê¶±ð
		vivo,sbu-pwr-gpio = <&pio 17 0>;
		ti,temp-cold-degc = <2>;
		ti,temp-hot-degc = <43>;
		vivo,total-limit-max-ma = <8000>;
		vivo,bigdata-collect-time-limit = <95>;//seconds
		vivo,direct-charger-enable;//porting_check

		/*FFC charge: */
		vivo,ffc-support;
		vivo,ffc-temperature-range = <150 450>;
		//vivo,ffc-param-tuning-enable = <1963>;
		vivo,ffc-cc-to-cv-ibat-thr-rc = <1 3>;
		/*<Tmin Tmax current>*/
		vivo,ffc-cc-to-cv-ibat-thr-table = <150 450 4900>;
		vivo,ffc-dchg-cv-mv-rc = <3 2>;
		/*btb_cv,fg_cv*/
		vivo,ffc-dchg-cv-mv-table = <4460 4460>,/*default*/
			<4534 4534>,/*single_charging*/
			<4534 4534>;/*dual_charging*/

		vivo,cout-int-gpio = <&pio 15 0>;

		vivo,sbu-cable-id-detect-enable;
		vivo,sbu-detect-rely-usb-switch;

		vivo,bat-board-temp-enable = <1>;
		vivo,usb-conn-temp-enable = <3>;
		vivo,bat-conn-temp-enable = <1>;

		vivo,master-bat-conn-temp-enable = <2>;
		vivo,dchg-exit-ntc-threshold = <700 650 700 700 1200>;

		/* BQ25970_SINGLE_DCHG:
		 * DCHG_SINGLE_TYPE_22P5W = 0,
		 * DCHG_SINGLE_TYPE_33W = 1,
		 * DCHG_SINGLE_TYPE_44W = 2,
		 * BQ25970_DUAL_DCHG:DCHG_DUAL_TYPE_44W = 3,
		 */
		vivo,dchg-supported-type = <2>;
		/*adapter power derate*/
		vivo,adapter-power-derate-enable;

		//vivo,single-charger-enable;
		vivo,adapter-sha-encryption;

		io-channels = <&auxadc 5>,
			<&auxadc 6>;

		io-channel-names = "sbu2_cable_id_adc",
			"sbu1_cable_id_adc";

		/*cable r limit table :
		  <rmin,rmax, dchg_ibus_max, cable_id_type, limit_count>
		  cable_id_type: 0:effective cable id, 1:other(default) cable id
		 */
		vivo,cable-r-limit-table-rc = <9 5>;
		vivo,cable-r-limit-table = <(-8888) 271 4000 0 0>,
			<272 329 3000 0 0>,
			<330 394 2250 0 0>,
			<395 505 1800 0 0>,
			<506 8888 0 0 0>,
			<(-8888) 329 3000 1 0>,
			<330 394 2250 1 0>,
			<395 505 1800 1 0>,
			<506 8888 0 1 0>;

		/*load firmware profile*/
		vivo,fw-id-range-pct = <100>;
		#include "bat_setting/mcu-firmware-data-44w-notbat_notbus.dtsi"
		#include "bat_setting/mcu-firmware-data-44w-ln8000-notbat-notbus.dtsi"
	};

	bq25890h@6a {
		compatible = "ti,bq25890h";
		reg = <0x6a>;

		//vivo,int-gpio = <&pio 44 0>;
	};

	bq25601d@6b {
		compatible = "ti,bq25601d";
		reg = <0x6b>;

		vivo,int-gpio = <&pio 44 0>;
		vivo,enable-gpio = <&pio 187 0>;
	};

	rt9467@5b {
		compatible = "richtek,rt9467";
		reg = <0x5b>;

		vivo,int-gpio = <&pio 44 0>;
		vivo,enable-gpio = <&pio 187 0>;
	};
};
#endif
/* Chris Lee add for battery&charge end */

/*************************
 * usb DTSI File
*************************/
&usb3_tune {
	u2_vrt_ref = <0x4>;
	u2_term_ref = <0x4>;
	u2_enhance = <0x3>;
	u2_discth = <0xa>;
	u2_vrt_ref_host = <0x6>;
	u2_term_ref_host = <0x5>;
	u2_enhance_host = <0x2>;
};
/* xudong add for audio config start */
&odm {
	vivo-audio-ktv@0 {
		compatible = "vivo,vivo-audio-ktv";
		status = "okay";
	};

	vivo-soc-codec@0 {
		compatible = "vivo,vivo-soc-codec";
		status = "okay";
	};

	typec_switch:typecswitch {
		compatible = "vivo,typec-switch";
		interrupt-parent = <&pio>;
		interrupts = <3 IRQ_TYPE_LEVEL_LOW 3 0>; /* usb plug in is low level */
		deb-gpios = <&pio 3 0>;
		debounce = <256000>;
		pinctrl-names = "default", "typec_eint_as_int";
		pinctrl-0 = <&typec_pins_default>;
		pinctrl-1 = <&typec_eint_as_int>;
		status = "okay";
	};
};

&pio {
	typec_pins_default: typecdefault {
	};
	typec_eint_as_int: typeceint@0 {
		pins_cmd_dat {
			pinmux = <PINMUX_GPIO3__FUNC_GPIO3>;
			slew-rate = <0>;
			bias-pull-up; /* prevent from leaking power */
			input-enable; /* not using default config */
		};
	};
};
&i2c8{
	tfa9894: tfa9894@34 {
		status = "okay";
		compatible = "nxp,tfa9894";
		#sound-dai-cells = <1>;
		reg = <0x34>;
		vivo,tfa98xx-version = "tfa9894";
		vivo,tfa98xx-config = "tfa98xx_PD2166F_EX.cnt";
		vivo,tfa98xx-impedance-min = <6000>;
		vivo,tfa98xx-impedance-max = <10000>;
		vivo,tfa98xx-frequency-min = <600>;
		vivo,tfa98xx-frequency-max = <900>;
		vivo,tfa98xx-Qt-min = <110>;
		reset-gpio = <&pio 139 0>;
	};
	max20328:max20328@15 {
		status = "okay";
		#sound-dai-cells = <0>;
		compatible = "maxin,max20328";
		reg = <0x15>;
		max,usbc-ic-mode = <0>; /* max20328: 0; fsa4480: 1 */
		jack-type = <1>;   /*0:3.5mm, 1:Type-c*/
		switch-type = <0>; /*0:max20328, 1:FS4480*/
	};
};
/* xudong add for audio config end */


/* add board info fdt node by corebsp begin */
&board_info {
	vivo,vendor_project_name = "PD2166F_EX";
	vivo,vendor_project_cpu = "MT6833";
	vivo,vendor_project_freq = "2.2";
	vivo,vendor_project_cpunum = <8>;
	vivo,vendor_cpu_set = "Dimensity_700";
};

&boards_version {
	pinctrl-names = "default";
	pinctrl-0 = <&board_version>;
	gpio_nums = <11>;
	gpios = <16 25 65 66 69 74 75 76 91 166 167>;
	/* if use pcb version,need to define:pcb_gpio_nums pcb_gpios pcb_maps_nums pcb_gpios_maps */
	/*pcb_gpio_nums = <2>;*/
	/*pcb_gpios = <107 108>;*/
	/* 00:MP_0.1, 01:MP_0.2, 10:MP_0.3, 11:MP_0.4 */
	/*pcb_maps_nums = <8>;*/
	/*pcb_gpios_maps = <0x0 0x1 0x1 0x2 0x2 0x3 0x3 0x4>;*/
};

&tcard_sim_slot {
	pinctrl-names = "default";
	pinctrl-0 = <&card_detect>;
	vivo,sim1-need-detect;
	vivo,sim2-need-detect;
	vivo,sim1-detect-high;
	vivo,sim2-detect-high;

        card-detect-sim1,gpios = <&pio 77 0x0>;
        card-detect-sim2,gpios = <&pio 77 0x0>;
};

&pio {
	board_version: hardware_board_version {
		pins_cmd0_dat {
			pinmux = <PINMUX_GPIO16__FUNC_GPIO16>;
			slew-rate = <0>;
		};
		pins_cmd1_dat {
			pinmux = <PINMUX_GPIO25__FUNC_GPIO25>;
			slew-rate = <0>;
		};
		pins_cmd2_dat {
			pinmux = <PINMUX_GPIO65__FUNC_GPIO65>;
			slew-rate = <0>;
		};
		pins_cmd3_dat {
			pinmux = <PINMUX_GPIO66__FUNC_GPIO66>;
			slew-rate = <0>;
		};
		pins_cmd4_dat {
			pinmux = <PINMUX_GPIO69__FUNC_GPIO69>;
			slew-rate = <0>;
		};
		pins_cmd5_dat {
			pinmux = <PINMUX_GPIO74__FUNC_GPIO74>;
			slew-rate = <0>;
		};
		pins_cmd6_dat {
			pinmux = <PINMUX_GPIO75__FUNC_GPIO75>;
			slew-rate = <0>;
		};
		pins_cmd7_dat {
			pinmux = <PINMUX_GPIO76__FUNC_GPIO76>;
			slew-rate = <0>;
		};
		pins_cmd8_dat {
			pinmux = <PINMUX_GPIO91__FUNC_GPIO91>;
			slew-rate = <0>;
		};
		pins_cmd9_dat {
			pinmux = <PINMUX_GPIO166__FUNC_GPIO166>;
			slew-rate = <0>;
		};
		pins_cmd10_dat {
			pinmux = <PINMUX_GPIO167__FUNC_GPIO167>;
			slew-rate = <0>;
		};
	};

	card_detect: card_sim_detect {
		pins_cmd0_dat {
			pinmux = <PINMUX_GPIO77__FUNC_MD_INT1_C2K_UIM0_HOT_PLUG>;
			slew-rate = <0>;
			bias-disable;
		};
		pins_cmd1_dat {
			pinmux = <PINMUX_GPIO78__FUNC_GPIO78>;
			slew-rate = <0>;
			bias-disable;
		};
	};
};
&vivo_md_co {
		gpio_for_md_co_load = <16>;
		gpio_value_for_new_modem = <1>;
};
/* add board info fdt node by corebsp end */
